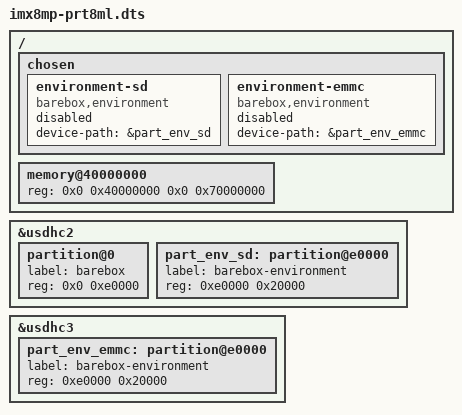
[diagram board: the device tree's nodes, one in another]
// SPDX-License-Identifier: (GPL-2.0 OR MIT)
/*
 * 2025 Pengutronix, Jonas Rebmann <kernel@pengutronix.de>
 */

/dts-v1/;
#include "imx8mp-prt8ml.dtsi"
#include "imx8mp.dtsi"

/ {
	chosen {
		environment-sd {
			compatible = "barebox,environment";
			device-path = &part_env_sd;
			status = "disabled";
		};
		environment-emmc {
			compatible = "barebox,environment";
			device-path = &part_env_emmc;
			status = "disabled";
		};
	};

	/* Minimum contiguous memory region is 1792MiB
	 * The probe function of the ddrc will either expand this
	 * to 6GiB (without ECC) or 5.25GiB (with inline ECC, in 3 regions).
	 */
	memory@40000000 {
		device_type = "memory";
		reg = <0x0 0x40000000 0x0 0x70000000>;
	};
};

&usdhc2 {
	#address-cells = <1>;
	#size-cells = <1>;

	partition@0 {
		label = "barebox";
		reg = <0x0 0xe0000>;
	};

	part_env_sd: partition@e0000 {
		label = "barebox-environment";
		reg = <0xe0000 0x20000>;
	};
};

&usdhc3 {
	#address-cells = <1>;
	#size-cells = <1>;

	part_env_emmc: partition@e0000 {
		label = "barebox-environment";
		reg = <0xe0000 0x20000>;
	};
};
